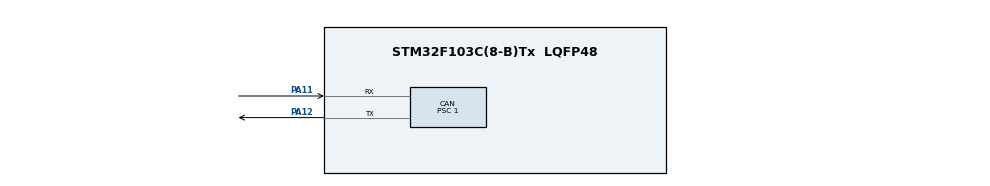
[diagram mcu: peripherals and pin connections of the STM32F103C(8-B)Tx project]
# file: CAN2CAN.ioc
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CAN.BS1=CAN_BS1_6TQ
CAN.CalculateBaudRate=1000000
CAN.CalculateTimeBit=1000
CAN.CalculateTimeQuantum=125.0
CAN.Prescaler=1
FREERTOS.INCLUDE_vTaskCleanUpResources=1
FREERTOS.INCLUDE_vTaskDelayUntil=1
FREERTOS.MEMORY_ALLOCATION=1
FREERTOS.Queues01=myQueue01,16,uint16_t,0,Static,myQueue01Buffer,myQueue01ControlBlock
FREERTOS.Tasks01=defaultTask,0,128,StartDefaultTask,Default,NULL,Static,defaultTaskBuffer,defaultTaskControlBlock
FREERTOS.configCHECK_FOR_STACK_OVERFLOW=2
FREERTOS.configGENERATE_RUN_TIME_STATS=1
FREERTOS.configUSE_COUNTING_SEMAPHORES=1
FREERTOS.configUSE_IDLE_HOOK=1
FREERTOS.configUSE_STATS_FORMATTING_FUNCTIONS=1
FREERTOS.configUSE_TRACE_FACILITY=1
Mcu.Family=STM32F1
Mcu.Name=STM32F103C(8-B)Tx
Mcu.Package=LQFP48
NVIC.CAN1_SCE_IRQn=true\:5\:0\:false\:false\:true\:true\:true\:true\:true
NVIC.PriorityGroup=NVIC_PRIORITYGROUP_4
NVIC.TIM1_UP_IRQn=true\:15\:0\:false\:false\:true\:false\:false\:true\:true
NVIC.TimeBase=TIM1_UP_IRQn
NVIC.TimeBaseIP=TIM1
NVIC.USB_HP_CAN1_TX_IRQn=true\:5\:0\:false\:false\:true\:true\:true\:true\:true
NVIC.USB_LP_CAN1_RX0_IRQn=true\:5\:0\:false\:false\:true\:true\:true\:true\:true
PA11.GPIO_PuPd=GPIO_PULLUP
PA11.Mode=CAN_Activate
PA11.Signal=CAN_RX
PA12.Mode=CAN_Activate
PA12.Signal=CAN_TX
PA13.Mode=Serial_Wire
PA13.Signal=SYS_JTMS-SWDIO
PA14.Mode=Serial_Wire
PA14.Signal=SYS_JTCK-SWCLK
ProjectManager.HeapSize=0x200
ProjectManager.StackSize=0x400
ProjectManager.TargetToolchain=Makefile
RCC.APB1Freq_Value=8000000
RCC.APB2Freq_Value=8000000
VP_FREERTOS_VS_CMSIS_V1.Mode=CMSIS_V1
VP_SYS_VS_tim1.Mode=TIM1
board=custom

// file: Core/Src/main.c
/* USER CODE BEGIN Header */
/**
 ******************************************************************************
 * @file           : main.c
 * @brief          : Main program body
 ******************************************************************************
 * @attention
 *
 * Copyright (c) 2023 STMicroelectronics.
 * All rights reserved.
 *
 * This software is licensed under terms that can be found in the LICENSE file
 * in the root directory of this software component.
 * If no LICENSE file comes with this software, it is provided AS-IS.
 *
 ******************************************************************************
 */
/* USER CODE END Header */
#include "main.h"
#include "can.h"
#include "cmsis_os.h"
#include "gpio.h"

/* USER CODE BEGIN Includes */
#include "can2can.h"
/* USER CODE END Includes */

void SystemClock_Config(void);
void MX_FREERTOS_Init(void);

int main(void) {

  /* MCU Configuration--------------------------------------------------------*/

  /* Reset of all peripherals, Initializes the Flash interface and the Systick. */
  HAL_Init();

  /* Configure the system clock */
  SystemClock_Config();

  /* Initialize all configured peripherals */
  MX_GPIO_Init();
  MX_CAN_Init();

  /* Call init function for freertos objects (in freertos.c) */
  // MX_FREERTOS_Init();

  /* Start scheduler */
  // osKernelStart();
  MasterNode_Initialize();
  SlaveNode_Initialize();

  vTaskStartScheduler();

  /* We should never get here as control is now taken by the scheduler */
  /* Infinite loop */
  while (1) {

  }
}

void SystemClock_Config(void) {
  RCC_OscInitTypeDef RCC_OscInitStruct = {0};
  RCC_ClkInitTypeDef RCC_ClkInitStruct = {0};

  /** Initializes the RCC Oscillators according to the specified parameters
   * in the RCC_OscInitTypeDef structure.
   */
  RCC_OscInitStruct.OscillatorType = RCC_OSCILLATORTYPE_HSI;
  RCC_OscInitStruct.HSIState = RCC_HSI_ON;
  RCC_OscInitStruct.HSICalibrationValue = RCC_HSICALIBRATION_DEFAULT;
  RCC_OscInitStruct.PLL.PLLState = RCC_PLL_NONE;
  if (HAL_RCC_OscConfig(&RCC_OscInitStruct) != HAL_OK) {
    Error_Handler();
  }

  /** Initializes the CPU, AHB and APB buses clocks
*/
  RCC_ClkInitStruct.ClockType = RCC_CLOCKTYPE_HCLK | RCC_CLOCKTYPE_SYSCLK |
                                RCC_CLOCKTYPE_PCLK1 | RCC_CLOCKTYPE_PCLK2;
  RCC_ClkInitStruct.SYSCLKSource = RCC_SYSCLKSOURCE_HSI;
  RCC_ClkInitStruct.AHBCLKDivider = RCC_SYSCLK_DIV1;
  RCC_ClkInitStruct.APB1CLKDivider = RCC_HCLK_DIV1;
  RCC_ClkInitStruct.APB2CLKDivider = RCC_HCLK_DIV1;

  if (HAL_RCC_ClockConfig(&RCC_ClkInitStruct, FLASH_LATENCY_0) != HAL_OK) {
    Error_Handler();
  }
}

void HAL_TIM_PeriodElapsedCallback(TIM_HandleTypeDef *htim) {
  if (htim->Instance == TIM1) {
    HAL_IncTick();
  }
}

void Error_Handler(void) {
  __disable_irq();
  while (1) {
  }
}

#ifdef USE_FULL_ASSERT
/**
 * @brief  Reports the name of the source file and the source line number
 *         where the assert_param error has occurred.
 * @param  file: pointer to the source file name
 * @param  line: assert_param error line source number
 * @retval None
 */
void assert_failed(uint8_t *file, uint32_t line) {
  /* USER CODE BEGIN 6 */
  /* User can add his own implementation to report the file name and line
     number, ex: printf("Wrong parameters value: file %s on line %d\r\n", file,
     line) */
  Error_Handler();
  (void)file;
  (void)line;
  /* USER CODE END 6 */
}
#endif /* USE_FULL_ASSERT */

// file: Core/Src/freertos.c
/* USER CODE BEGIN Header */
/**
 ******************************************************************************
 * File Name          : freertos.c
 * Description        : Code for freertos applications
 ******************************************************************************
 * @attention
 *
 * Copyright (c) 2023 STMicroelectronics.
 * All rights reserved.
 *
 * This software is licensed under terms that can be found in the LICENSE file
 * in the root directory of this software component.
 * If no LICENSE file comes with this software, it is provided AS-IS.
 *
 ******************************************************************************
 */
/* USER CODE END Header */

#include "FreeRTOS.h"
#include "cmsis_os.h"
#include "main.h"
#include "task.h"

/* USER CODE BEGIN Variables */

/* timer stack memory */
static StackType_t timerTaskStackMemory [configTIMER_TASK_STACK_DEPTH] = {0};
static StaticTask_t timerTaskBuffer = {0};

/* USER CODE END Variables */
osThreadId defaultTaskHandle;
uint32_t defaultTaskBuffer[128];
osStaticThreadDef_t defaultTaskControlBlock;

osMessageQId myQueue01Handle;
uint8_t myQueue01Buffer[16 * sizeof(uint16_t)];
osStaticMessageQDef_t myQueue01ControlBlock;

void StartDefaultTask(void const *argument);

void MX_FREERTOS_Init(void); /* (MISRA C 2004 rule 8.1) */

/* GetIdleTaskMemory prototype (linked to static allocation support) */
void vApplicationGetIdleTaskMemory(StaticTask_t **ppxIdleTaskTCBBuffer, StackType_t **ppxIdleTaskStackBuffer, uint32_t *pulIdleTaskStackSize);

/* Hook prototypes */
void configureTimerForRunTimeStats(void);
unsigned long getRunTimeCounterValue(void);
void vApplicationIdleHook(void);
void vApplicationStackOverflowHook(xTaskHandle xTask, signed char *pcTaskName);

/* USER CODE BEGIN 1 */
/* Functions needed when configGENERATE_RUN_TIME_STATS is on */

void vApplicationGetTimerTaskMemory(StaticTask_t **ppxTimerTaskTCBBuffer, StackType_t **ppxTimerTaskStackBuffer, uint32_t *pulTimerTaskStackSize) {
  uint32_t timer_task_stack_size = configTIMER_TASK_STACK_DEPTH;

  (*ppxTimerTaskTCBBuffer) = &timerTaskBuffer;
  (*ppxTimerTaskStackBuffer) = timerTaskStackMemory;
  (*pulTimerTaskStackSize) = timer_task_stack_size;
}

__weak void configureTimerForRunTimeStats(void) {}

__weak unsigned long getRunTimeCounterValue(void) { return HAL_GetTick(); }
/* USER CODE END 1 */

/* USER CODE BEGIN 2 */
__weak void vApplicationIdleHook(void) {
  /* vApplicationIdleHook() will only be called if configUSE_IDLE_HOOK is set
  to 1 in FreeRTOSConfig.h. It will be called on each iteration of the idle
  task. It is essential that code added to this hook function never attempts
  to block in any way (for example, call xQueueReceive() with a block time
  specified, or call vTaskDelay()). If the application makes use of the
  vTaskDelete() API function (as this demo application does) then it is also
  important that vApplicationIdleHook() is permitted to return to its calling
  function, because it is the responsibility of the idle task to clean up
  memory allocated by the kernel to any task that has since been deleted. */
}
/* USER CODE END 2 */

/* USER CODE BEGIN 4 */
__weak void vApplicationStackOverflowHook(xTaskHandle xTask,
                                          signed char *pcTaskName) {
  /* Run time stack overflow checking is performed if
  configCHECK_FOR_STACK_OVERFLOW is defined to 1 or 2. This hook function is
  called if a stack overflow is detected. */
}
/* USER CODE END 4 */

/* USER CODE BEGIN GET_IDLE_TASK_MEMORY */
static StaticTask_t xIdleTaskTCBBuffer;
static StackType_t xIdleStack[configMINIMAL_STACK_SIZE];

void vApplicationGetIdleTaskMemory(StaticTask_t **ppxIdleTaskTCBBuffer, StackType_t **ppxIdleTaskStackBuffer, uint32_t *pulIdleTaskStackSize) {
  *ppxIdleTaskTCBBuffer = &xIdleTaskTCBBuffer;
  *ppxIdleTaskStackBuffer = &xIdleStack[0];
  *pulIdleTaskStackSize = configMINIMAL_STACK_SIZE;
  /* place for user code */
}
/* USER CODE END GET_IDLE_TASK_MEMORY */

void MX_FREERTOS_Init(void) {

  /* Create the queue(s) */
  /* definition and creation of myQueue01 */
  osMessageQStaticDef(myQueue01, 16, uint16_t, myQueue01Buffer, &myQueue01ControlBlock);
  myQueue01Handle = osMessageCreate(osMessageQ(myQueue01), NULL);

  /* Create the thread(s) */
  /* definition and creation of defaultTask */
  osThreadStaticDef(defaultTask, StartDefaultTask, osPriorityNormal, 0, 128, defaultTaskBuffer, &defaultTaskControlBlock);
  defaultTaskHandle = osThreadCreate(osThread(defaultTask), NULL);

}

void StartDefaultTask(void const *argument) {
  for (;;) {
    osDelay(1);
  }
}
